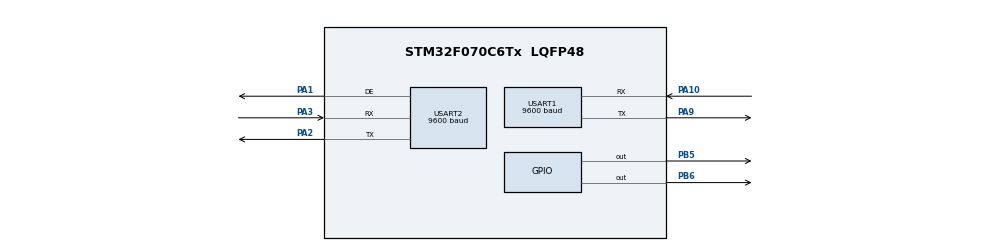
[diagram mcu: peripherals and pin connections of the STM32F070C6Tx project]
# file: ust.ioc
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Mcu.Family=STM32F0
Mcu.Name=STM32F070C6Tx
Mcu.Package=LQFP48
NVIC.TIM14_IRQn=true\:0\:0\:false\:false\:true\:true\:true
NVIC.USART1_IRQn=true\:0\:0\:false\:false\:true\:true\:true
NVIC.USART2_IRQn=true\:0\:0\:false\:false\:true\:true\:true
PA1.Mode=Hardware Flow Control (RS485)
PA1.Signal=USART2_DE
PA10.Mode=Asynchronous
PA10.Signal=USART1_RX
PA2.Mode=Asynchronous
PA2.Signal=USART2_TX
PA3.Mode=Asynchronous
PA3.Signal=USART2_RX
PA9.Mode=Asynchronous
PA9.Signal=USART1_TX
PB5.Signal=GPIO_Output
PB6.Signal=GPIO_Output
ProjectManager.HeapSize=0x200
ProjectManager.StackSize=0x400
ProjectManager.TargetToolchain=Makefile
USART1.BaudRate=9600
USART1.VirtualMode-Asynchronous=VM_ASYNC
USART2.BaudRate=9600
USART2.VirtualMode-Asynchronous=VM_ASYNC
USART2.VirtualMode-Hardware\ Flow\ Control\ (RS485)=VM_ASYNC
VP_TIM14_VS_ClockSourceINT.Mode=Enable_Timer
board=custom

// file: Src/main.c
/* USER CODE BEGIN Header */
/**
  ******************************************************************************
  * @file           : main.c
  * @brief          : Main program body
  ******************************************************************************
  * @attention
  *
  * <h2><center>&copy; Copyright (c) 2019 STMicroelectronics.
  * All rights reserved.</center></h2>
  *
  * This software component is licensed by ST under BSD 3-Clause license,
  * the "License"; You may not use this file except in compliance with the
  * License. You may obtain a copy of the License at:
  *                        opensource.org/licenses/BSD-3-Clause
  *
  ******************************************************************************
  */
/* USER CODE END Header */

#include "main.h"
#include "mb.h"
#include "mbport.h"

TIM_HandleTypeDef htim14;

UART_HandleTypeDef huart1;
UART_HandleTypeDef huart2;

/* USER CODE BEGIN PV */
//  uint8_t received[4];
 //uint8_t status=0;
//  uint8_t str[]="usrt";
/* USER CODE END PV */

void SystemClock_Config(void);
static void MX_GPIO_Init(void);
static void MX_USART1_UART_Init(void);
static void MX_USART2_UART_Init(void);
static void MX_TIM14_Init(void);

/* USER CODE BEGIN 0 */
// void HAL_UART_RxCpltCallback(UART_HandleTypeDef *huart)
// {
//   /* Prevent unused argument(s) compilation warning */
//     if(huart==&huart1){
//       status=1;
//       HAL_UART_Receive_IT(&huart1, received, sizeof(received));
//     }
//   /* NOTE : This function should not be modified, when the callback is needed,
//             the HAL_UART_RxCpltCallback can be implemented in the user file.
//    */
// }

//static char header[] = "PA4  PA5  PA6  PA7\r\n";
//static char headerb[] = "PB12 PB13 PB14 PB15\r\n";

//static char open[]="o    ";
//static char close[]="c    ";
// void test(){
//   uint16_t gpionum=0x0010U;
//     HAL_UART_Transmit(&huart1,(uint8_t*)header,sizeof(header),30);
//     for (int i = 0; i < 4; i++)
//      {
//         if(HAL_GPIO_ReadPin(GPIOA,gpionum)==GPIO_PIN_SET){
//           HAL_UART_Transmit(&huart1,(uint8_t*)open,sizeof(open),30);
//         }else{
//           HAL_UART_Transmit(&huart1,(uint8_t*)close,sizeof(close),30);
//         }
//           gpionum=gpionum*2;
//      }
//     HAL_UART_Transmit(&huart1,(uint8_t*)"\r\n",2,30);
//     HAL_UART_Transmit(&huart1,(uint8_t*)headerb,sizeof(headerb),30);
//     gpionum=0x1000U;
//      for (int i = 0; i < 4; i++)
//      {
//         if(HAL_GPIO_ReadPin(GPIOB,gpionum)==GPIO_PIN_SET){
//            HAL_UART_Transmit(&huart1,(uint8_t*)open,sizeof(open),30);
//         }else{
//            HAL_UART_Transmit(&huart1,(uint8_t*)close,sizeof(close),30);
//          }
//           gpionum=gpionum*2;
//      }
//      HAL_UART_Transmit(&huart1,(uint8_t*)"\r\nGreen: ",9,30);
//      if (HAL_GPIO_ReadPin(GPIOB,GPIO_PIN_6)==GPIO_PIN_SET)
//      {
//        HAL_UART_Transmit(&huart1,(uint8_t*)"on", 2, 30);
//      }else{
//        HAL_UART_Transmit(&huart1,(uint8_t*)"off", 3, 30);
//      }
//       HAL_UART_Transmit(&huart1,(uint8_t*)"\r\nRed: ",7,30);
//      if (HAL_GPIO_ReadPin(GPIOB,GPIO_PIN_5)==GPIO_PIN_SET)
//        {
//         HAL_UART_Transmit(&huart1,(uint8_t*)"on", 2, 30);
//        }else{
//         HAL_UART_Transmit(&huart1,(uint8_t*)"off", 3, 30);
//        }
//      HAL_UART_Transmit(&huart1,(uint8_t*)"\r\n\n",3,30);

// }

/* USER CODE END 0 */

int main(void)
{

  /* MCU Configuration--------------------------------------------------------*/

  /* Reset of all peripherals, Initializes the Flash interface and the Systick. */
  HAL_Init();

  /* Configure the system clock */
  SystemClock_Config();

  /* Initialize all configured peripherals */
  MX_GPIO_Init();
  MX_USART1_UART_Init();
  MX_USART2_UART_Init();
  MX_TIM14_Init();
  /* USER CODE BEGIN 2 */
//  HAL_UART_Receive_IT(&huart1, received, sizeof(received));
  HAL_NVIC_SetPriority(USART1_IRQn, 0, 1);
  HAL_NVIC_EnableIRQ(USART1_IRQn);
  xMBPortTimersInit( 20 );
  vMBPortTimersEnable( );
  eMBInit(MB_RTU,0x0A, 1,9600, MB_PAR_NONE);
  eMBEnable();
  /* USER CODE END 2 */

  /* Infinite loop */
  /* USER CODE BEGIN WHILE */
  while (1)
  {
    eMBPoll();
     /*  if(status==1 && received[0]=='t'){
        test();
        received[0]=0;
      }

      state=HAL_UART_Transmit(&huart2,(uint8_t*)"test\r\n",6,100);
      if(state==HAL_OK){
          HAL_GPIO_TogglePin(GPIOB,GPIO_PIN_5);
      }
      HAL_Delay(1000);*/

    /* USER CODE END WHILE */

  }
}

void SystemClock_Config(void)
{
  RCC_OscInitTypeDef RCC_OscInitStruct = {0};
  RCC_ClkInitTypeDef RCC_ClkInitStruct = {0};
  RCC_PeriphCLKInitTypeDef PeriphClkInit = {0};

  /** Initializes the CPU, AHB and APB busses clocks
  */
  RCC_OscInitStruct.OscillatorType = RCC_OSCILLATORTYPE_HSI;
  RCC_OscInitStruct.HSIState = RCC_HSI_ON;
  RCC_OscInitStruct.HSICalibrationValue = RCC_HSICALIBRATION_DEFAULT;
  RCC_OscInitStruct.PLL.PLLState = RCC_PLL_NONE;
  if (HAL_RCC_OscConfig(&RCC_OscInitStruct) != HAL_OK)
  {
    Error_Handler();
  }
  /** Initializes the CPU, AHB and APB busses clocks
  */
  RCC_ClkInitStruct.ClockType = RCC_CLOCKTYPE_HCLK|RCC_CLOCKTYPE_SYSCLK
                              |RCC_CLOCKTYPE_PCLK1;
  RCC_ClkInitStruct.SYSCLKSource = RCC_SYSCLKSOURCE_HSI;
  RCC_ClkInitStruct.AHBCLKDivider = RCC_SYSCLK_DIV1;
  RCC_ClkInitStruct.APB1CLKDivider = RCC_HCLK_DIV1;

  if (HAL_RCC_ClockConfig(&RCC_ClkInitStruct, FLASH_LATENCY_0) != HAL_OK)
  {
    Error_Handler();
  }
  PeriphClkInit.PeriphClockSelection = RCC_PERIPHCLK_USART1;
  PeriphClkInit.Usart1ClockSelection = RCC_USART1CLKSOURCE_PCLK1;
  if (HAL_RCCEx_PeriphCLKConfig(&PeriphClkInit) != HAL_OK)
  {
    Error_Handler();
  }
}

static void MX_TIM14_Init(void)
{

  htim14.Instance = TIM14;
  htim14.Init.Prescaler = 0;
  htim14.Init.CounterMode = TIM_COUNTERMODE_UP;
  htim14.Init.Period = 0;
  htim14.Init.ClockDivision = TIM_CLOCKDIVISION_DIV1;
  htim14.Init.AutoReloadPreload = TIM_AUTORELOAD_PRELOAD_DISABLE;
  if (HAL_TIM_Base_Init(&htim14) != HAL_OK)
  {
    Error_Handler();
  }

}

static void MX_USART1_UART_Init(void)
{

  huart1.Instance = USART1;
  huart1.Init.BaudRate = 9600;
  huart1.Init.WordLength = UART_WORDLENGTH_8B;
  huart1.Init.StopBits = UART_STOPBITS_1;
  huart1.Init.Parity = UART_PARITY_NONE;
  huart1.Init.Mode = UART_MODE_TX_RX;
  huart1.Init.HwFlowCtl = UART_HWCONTROL_NONE;
  huart1.Init.OverSampling = UART_OVERSAMPLING_16;
  huart1.Init.OneBitSampling = UART_ONE_BIT_SAMPLE_DISABLE;
  huart1.AdvancedInit.AdvFeatureInit = UART_ADVFEATURE_NO_INIT;
  if (HAL_UART_Init(&huart1) != HAL_OK)
  {
    Error_Handler();
  }

}

static void MX_USART2_UART_Init(void)
{

  huart2.Instance = USART2;
  huart2.Init.BaudRate = 9600;
  huart2.Init.WordLength = UART_WORDLENGTH_8B;
  huart2.Init.StopBits = UART_STOPBITS_1;
  huart2.Init.Parity = UART_PARITY_NONE;
  huart2.Init.Mode = UART_MODE_TX_RX;
  huart2.Init.HwFlowCtl = UART_HWCONTROL_NONE;
  huart2.Init.OverSampling = UART_OVERSAMPLING_16;
  huart2.Init.OneBitSampling = UART_ONE_BIT_SAMPLE_DISABLE;
  huart2.AdvancedInit.AdvFeatureInit = UART_ADVFEATURE_NO_INIT;
  if (HAL_RS485Ex_Init(&huart2, UART_DE_POLARITY_HIGH, 0, 0) != HAL_OK)
  {
    Error_Handler();
  }

}

static void MX_GPIO_Init(void)
{
  GPIO_InitTypeDef GPIO_InitStruct = {0};

  /* GPIO Ports Clock Enable */
  __HAL_RCC_GPIOA_CLK_ENABLE();
  __HAL_RCC_GPIOB_CLK_ENABLE();

  /*Configure GPIO pin Output Level */
  HAL_GPIO_WritePin(GPIOB, GPIO_PIN_5|GPIO_PIN_6, GPIO_PIN_RESET);

  /*Configure GPIO pins : PB5 PB6 */
  GPIO_InitStruct.Pin = GPIO_PIN_5|GPIO_PIN_6;
  GPIO_InitStruct.Mode = GPIO_MODE_OUTPUT_PP;
  GPIO_InitStruct.Pull = GPIO_NOPULL;
  GPIO_InitStruct.Speed = GPIO_SPEED_FREQ_LOW;
  HAL_GPIO_Init(GPIOB, &GPIO_InitStruct);

}

void Error_Handler(void)
{
}

/************************ (C) COPYRIGHT STMicroelectronics *****END OF FILE****/
